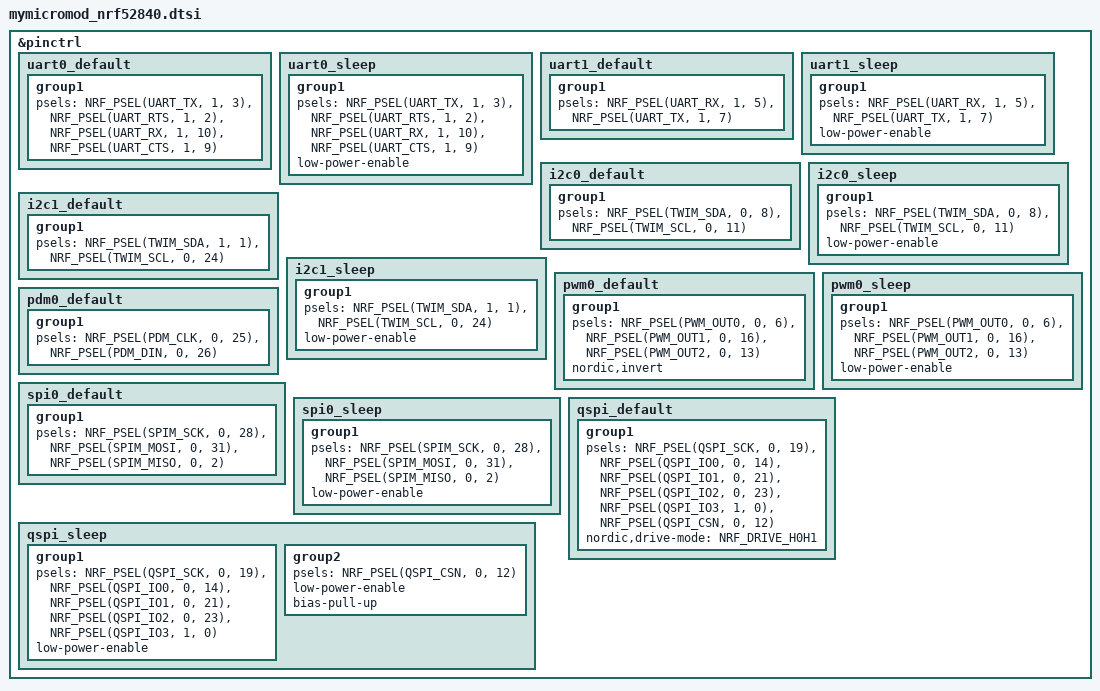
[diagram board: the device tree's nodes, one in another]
/*
 * Copyright (c) 2024 Abdulrahman Aminu <aminuabdulrahmandayo@gmail.com>
 *
 * SPDX-License-Identifier: Apache-2.0
 */

&pinctrl {
	uart0_default: uart0_default {
		group1 {
			psels = <NRF_PSEL(UART_TX, 1, 3)>,
			        <NRF_PSEL(UART_RTS, 1, 2)>,
			        <NRF_PSEL(UART_RX, 1, 10)>,
			        <NRF_PSEL(UART_CTS, 1, 9)>;
		};

	};

	uart0_sleep: uart0_sleep {
		group1 {
			psels = <NRF_PSEL(UART_TX, 1, 3)>,
			        <NRF_PSEL(UART_RTS, 1, 2)>,
			        <NRF_PSEL(UART_RX, 1, 10)>,
			        <NRF_PSEL(UART_CTS, 1, 9)>;
			low-power-enable;
		};
	};

	uart1_default: uart1_default {
		group1 {
			psels = <NRF_PSEL(UART_RX, 1, 5)>,
					<NRF_PSEL(UART_TX, 1, 7)>;
		};
	};

	uart1_sleep: uart1_sleep {
		group1 {
			psels = <NRF_PSEL(UART_RX, 1, 5)>,
					<NRF_PSEL(UART_TX, 1, 7)>;
			low-power-enable;
		};
	};

	i2c0_default: i2c0_default {
		group1 {
			psels = <NRF_PSEL(TWIM_SDA, 0, 8)>,
					<NRF_PSEL(TWIM_SCL, 0, 11)>;
		};
	};

	i2c0_sleep: i2c0_sleep {
		group1 {
			psels = <NRF_PSEL(TWIM_SDA, 0, 8)>,
					<NRF_PSEL(TWIM_SCL, 0, 11)>;
			low-power-enable;
		};
	};

	i2c1_default: i2c1_default {
		group1 {
			psels = <NRF_PSEL(TWIM_SDA, 1, 1)>,
					<NRF_PSEL(TWIM_SCL, 0, 24)>;
		};
	};

	i2c1_sleep: i2c1_sleep {
		group1 {
			psels = <NRF_PSEL(TWIM_SDA, 1, 1)>,
					<NRF_PSEL(TWIM_SCL, 0, 24)>;
			low-power-enable;
		};
	};

	pwm0_default: pwm0_default {
		group1 {
			psels = <NRF_PSEL(PWM_OUT0, 0, 6)>,
			        <NRF_PSEL(PWM_OUT1, 0, 16)>,
			        <NRF_PSEL(PWM_OUT2, 0, 13)>;
			nordic,invert;
		};


	};

	pwm0_sleep: pwm0_sleep {
		group1 {
			psels = <NRF_PSEL(PWM_OUT0, 0, 6)>,
			        <NRF_PSEL(PWM_OUT1, 0, 16)>,
			        <NRF_PSEL(PWM_OUT2, 0, 13)>;
			low-power-enable;
		};
	};


	pdm0_default: pdm0_default {
		group1 {
			psels = <NRF_PSEL(PDM_CLK, 0, 25)>,
					<NRF_PSEL(PDM_DIN, 0, 26)>;
		};
	};

	spi0_default: spi0_default {
		group1 {
			psels = <NRF_PSEL(SPIM_SCK, 0, 28)>,
			        <NRF_PSEL(SPIM_MOSI, 0, 31)>,
			        <NRF_PSEL(SPIM_MISO, 0, 2)>;
		};
	};

	spi0_sleep: spi0_sleep {
		group1 {
			psels = <NRF_PSEL(SPIM_SCK, 0, 28)>,
			        <NRF_PSEL(SPIM_MOSI, 0, 31)>,
			        <NRF_PSEL(SPIM_MISO, 0, 2)>;
			low-power-enable;
		};
	};


	qspi_default: qspi_default {
		group1 {
			psels = <NRF_PSEL(QSPI_SCK, 0, 19)>,
			        <NRF_PSEL(QSPI_IO0, 0, 14)>,
			        <NRF_PSEL(QSPI_IO1, 0, 21)>,
			        <NRF_PSEL(QSPI_IO2, 0, 23)>,
			        <NRF_PSEL(QSPI_IO3, 1, 0)>,
			        <NRF_PSEL(QSPI_CSN, 0, 12)>;
			nordic,drive-mode = <NRF_DRIVE_H0H1>;
		};
	};

	qspi_sleep: qspi_sleep {
		group1 {
			psels = <NRF_PSEL(QSPI_SCK, 0, 19)>,
			        <NRF_PSEL(QSPI_IO0, 0, 14)>,
			        <NRF_PSEL(QSPI_IO1, 0, 21)>,
			        <NRF_PSEL(QSPI_IO2, 0, 23)>,
			        <NRF_PSEL(QSPI_IO3, 1, 0)>;
			low-power-enable;
		};
		group2 {
			psels = <NRF_PSEL(QSPI_CSN, 0, 12)>;
			low-power-enable;
			bias-pull-up;
		};
	};

};
